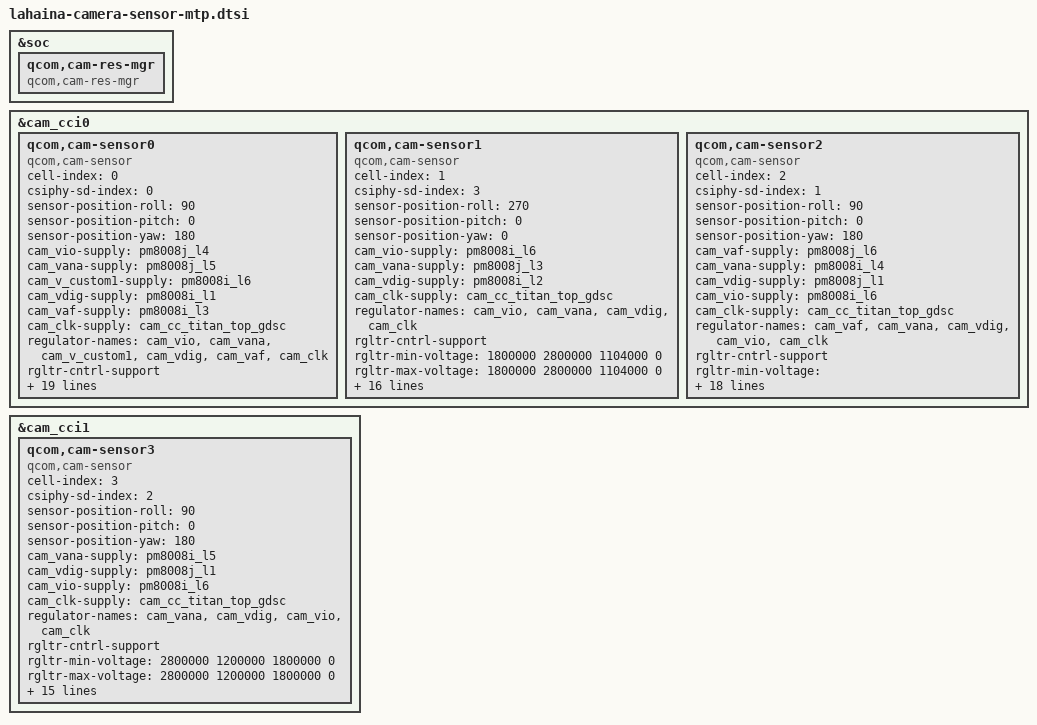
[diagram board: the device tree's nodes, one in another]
#include <dt-bindings/clock/qcom,camcc-lahaina.h>

&soc {

	qcom,cam-res-mgr {
		compatible = "qcom,cam-res-mgr";
		status = "ok";
	};
};

&cam_cci0 {

		//########### IMX686 16M ###########
	qcom,cam-sensor0 {
		cell-index = <0>;
		compatible = "qcom,cam-sensor";
		csiphy-sd-index = <0>;
		sensor-position-roll = <90>;
		sensor-position-pitch = <0>;
		sensor-position-yaw = <180>;
		//eeprom-src = <&eeprom_triple_tele>;
		//actuator-src = <&actuator_triple_tele>;
		//led-flash-src = <&led_flash_triple_rear_aux>;
		cam_vio-supply = <&pm8008j_l4>;      //CAM_AVDD1_2P9
		cam_vana-supply = <&pm8008j_l5>;      //CAM_AVDD_1P8
		cam_v_custom1-supply = <&pm8008i_l6>;    //MCAM0_DOVDD_T_1P8
		cam_vdig-supply = <&pm8008i_l1>;         //MCAM0_DVDD_T_1P1
		cam_vaf-supply = <&pm8008i_l3>;          //MVCM_2P8
		cam_clk-supply = <&cam_cc_titan_top_gdsc>;
		regulator-names = "cam_vio", "cam_vana", "cam_v_custom1", "cam_vdig", "cam_vaf", "cam_clk";
		
		rgltr-cntrl-support;
		rgltr-min-voltage = <2900000 1800000 1800000 1104000 2856000 0>;
		rgltr-max-voltage = <2900000 1800000 1800000 1104000 2856000 0>;
		rgltr-load-current = <0 80000 80000 0 0 0>;
		gpio-no-mux = <0>;
		pinctrl-names = "cam_default", "cam_suspend";
		pinctrl-0 = <&cam_sensor_mclk0_active
				&cam_sensor_active_rst0>;
		pinctrl-1 = <&cam_sensor_mclk0_suspend
				&cam_sensor_suspend_rst0>;
		gpios = <&tlmm 100 0>,
			<&tlmm 17 0>;
		gpio-reset = <1>;
		gpio-req-tbl-num = <0 1>;
		gpio-req-tbl-flags = <1 0>;
		gpio-req-tbl-label = "CAMIF_MCLK0",
					"CAM_RESET0";
		cci-master = <0>;
		status = "ok";
		clocks = <&clock_camcc CAM_CC_MCLK0_CLK>;
		clock-names = "cam_clk";
		clock-cntl-level = "nominal";
		clock-rates = <19200000>;
	};
	
			//########### Front OV24B1Q 24M ###########
	qcom,cam-sensor1 {
		cell-index = <1>;
		compatible = "qcom,cam-sensor";
		csiphy-sd-index = <3>;
		sensor-position-roll = <270>;
		sensor-position-pitch = <0>;
		sensor-position-yaw = <0>;
		//actuator-src = <&actuator_triple_wide>;
		//eeprom-src = <&eeprom_triple_wide>;
		//led-flash-src = <&led_flash_triple_rear>;
		
		cam_vio-supply = <&pm8008i_l6>;			    //PM8008_LDO6_1P8
		cam_vana-supply = <&pm8008j_l3>;		    //CAM3_AVDD_2P8
		cam_vdig-supply = <&pm8008i_l2>;			//PM8008_LDO2_1P1
		cam_clk-supply = <&cam_cc_titan_top_gdsc>;

		regulator-names = "cam_vio", "cam_vana", "cam_vdig", "cam_clk";
		rgltr-cntrl-support;
		rgltr-min-voltage = <1800000 2800000 1104000 0>;
		rgltr-max-voltage = <1800000 2800000 1104000 0>;
		rgltr-load-current = <0 80000 1200000 0 >;
		gpio-no-mux = <0>;
		pinctrl-names = "cam_default", "cam_suspend";
		pinctrl-0 = <&cam_sensor_mclk3_active
				 &cam_sensor_active_rst3>;
		pinctrl-1 = <&cam_sensor_mclk3_suspend
				 &cam_sensor_suspend_rst3>;
		gpios = <&tlmm 103 0>,
			<&tlmm 106 0>;
		gpio-reset = <1>;
		gpio-req-tbl-num = <0 1>;
		gpio-req-tbl-flags = <1 0>;
		gpio-req-tbl-label = "CAMIF_MCLK3",
					"CAM_RESET3";
		sensor-mode = <0>;
		cci-master = <1>;
		status = "ok";
		clocks = <&clock_camcc CAM_CC_MCLK3_CLK>;
		clock-names = "cam_clk";
		clock-cntl-level = "nominal";
		clock-rates = <19200000>;
	};
	
		//######## OV13855 #########
	qcom,cam-sensor2 {
		cell-index = <2>;
		compatible = "qcom,cam-sensor";
		csiphy-sd-index = <1>;
		sensor-position-roll = <90>;
		sensor-position-pitch = <0>;
		sensor-position-yaw = <180>;
		//actuator-src = <&actuator_triple_wide>;
		//eeprom-src = <&eeprom_triple_wide>;
		//led-flash-src = <&led_flash_triple_rear>;
		cam_vaf-supply = <&pm8008j_l6>;         //MCAM1_AF_AVDD_W_2P8
		cam_vana-supply = <&pm8008i_l4>;     	//CAM_AVDD_2P8
		cam_vdig-supply = <&pm8008j_l1>;        //MCAM1_DVDD_W_1P2		
		cam_vio-supply = <&pm8008i_l6>;      	//MCAM1_DOVDD_W_1P8		
		cam_clk-supply = <&cam_cc_titan_top_gdsc>;
		regulator-names = "cam_vaf", "cam_vana", "cam_vdig"," cam_vio", "cam_clk";
		rgltr-cntrl-support;
		rgltr-min-voltage = <2800000 2800000 1200000 1800000 0>;
		rgltr-max-voltage = <2800000 2800000 1200000 1800000 0>;
		rgltr-load-current = <0 80000 1200000 0 0>;
		gpio-no-mux = <0>;
		pinctrl-names = "cam_default", "cam_suspend";
		pinctrl-0 = <&cam_sensor_mclk1_active
				&cam_sensor_active_rst1>;
		pinctrl-1 = <&cam_sensor_mclk1_suspend
				&cam_sensor_suspend_rst1>;
		gpios = <&tlmm 101 0>,
			<&tlmm 16 0>;
		gpio-reset = <1>;
		gpio-req-tbl-num = <0 1>;
		gpio-req-tbl-flags = <1 0>;
		gpio-req-tbl-label = "CAMIF_MCLK1",
					"CAM_RESET1";
		cci-master = <1>;
		status = "ok";
		clocks = <&clock_camcc CAM_CC_MCLK1_CLK>;
		clock-names = "cam_clk";
		clock-cntl-level = "nominal";
		clock-rates = <19200000>;
	};
};
&cam_cci1 {

	//	########### Rear OV8856  8M AF ###########
	qcom,cam-sensor3 {
		cell-index = <3>;
		compatible = "qcom,cam-sensor";
		csiphy-sd-index = <2>;
		sensor-position-roll = <90>;
		sensor-position-pitch = <0>;
		sensor-position-yaw = <180>;
		//eeprom-src = <&eeprom_triple_uw>;
		//actuator-src = <&actuator_triple_uw>;
		//led-flash-src = <&led_flash_triple_rear_aux2>;
		cam_vana-supply = <&pm8008i_l5>;			//CAM2_AVDD_2P8_EN   //PM8008_LDO5_2P8
		cam_vdig-supply = <&pm8008j_l1>;		//CAM_DVDD_AF_1P2    //PM8008_2_LDO1_1P2
		cam_vio-supply = <&pm8008i_l6>;			//CAM_DOVDD_AF_1P8   //PM8008_LDO6_1P8
		cam_clk-supply = <&cam_cc_titan_top_gdsc>;
		regulator-names = "cam_vana", "cam_vdig", "cam_vio", "cam_clk";
		rgltr-cntrl-support;
		rgltr-min-voltage = <2800000 1200000 1800000 0>;
		rgltr-max-voltage = <2800000 1200000 1800000 0>;
		rgltr-load-current = <0 80000 1200000 0 >;
		gpio-no-mux = <0>;
		pinctrl-names = "cam_default", "cam_suspend";
		pinctrl-0 = <&cam_sensor_mclk2_active
				 &cam_sensor_active_rst2>;
		pinctrl-1 = <&cam_sensor_mclk2_suspend
				 &cam_sensor_suspend_rst2>;
		gpios = <&tlmm 102 0>,
			<&tlmm 117 0>;
		gpio-reset = <1>;
		gpio-req-tbl-num = <0 1>;
		gpio-req-tbl-flags = <1 0>;
		gpio-req-tbl-label = "CAMIF_MCLK2",
					"CAM_RESET2";
		cci-master = <0>;
		status = "ok";
		clocks = <&clock_camcc CAM_CC_MCLK2_CLK>;
		clock-names = "cam_clk";
		clock-cntl-level = "nominal";
		clock-rates = <19200000>;
	};
};
